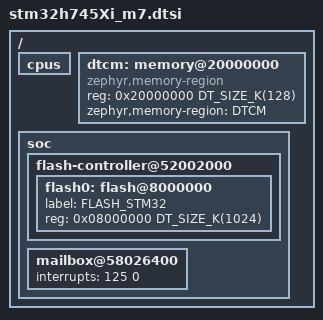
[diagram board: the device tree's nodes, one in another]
/*
 * Copyright (c) 2020 Alexander Kozhinov <AlexanderKozhinov@yandex.com>
 *
 * SPDX-License-Identifier: Apache-2.0
 */

#include <mem.h>
#include <st/h7/stm32h745.dtsi>

/delete-node/ &flash1;

/ {
	cpus {
		/delete-node/ cpu@1;
	};

	dtcm: memory@20000000 {
		compatible = "zephyr,memory-region", "arm,dtcm";
		reg = <0x20000000 DT_SIZE_K(128)>;
		zephyr,memory-region = "DTCM";
	};

	soc {
		flash-controller@52002000 {
			flash0: flash@8000000 {
				label = "FLASH_STM32";
				reg = <0x08000000 DT_SIZE_K(1024)>;
			};
		};

		mailbox@58026400 {
			interrupts = <125 0>;
		};
	};
};
